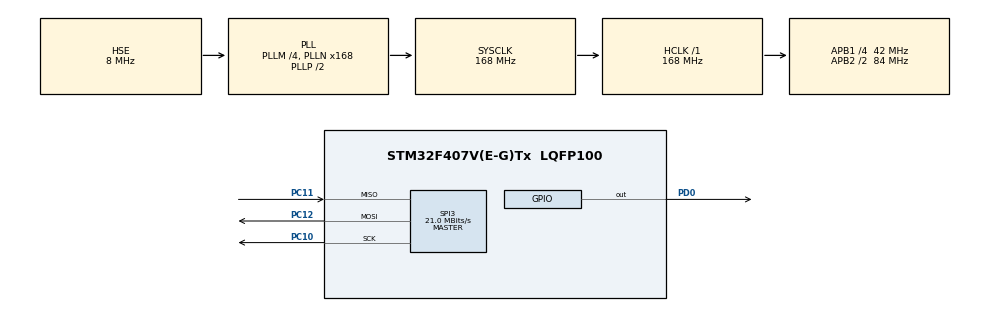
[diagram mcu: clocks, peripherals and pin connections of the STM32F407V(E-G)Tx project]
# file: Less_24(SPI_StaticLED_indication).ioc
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Mcu.Family=STM32F4
Mcu.Name=STM32F407V(E-G)Tx
Mcu.Package=LQFP100
NVIC.PriorityGroup=NVIC_PRIORITYGROUP_4
PC10.Mode=Full_Duplex_Master
PC10.Signal=SPI3_SCK
PC11.Mode=Full_Duplex_Master
PC11.Signal=SPI3_MISO
PC12.Mode=Full_Duplex_Master
PC12.Signal=SPI3_MOSI
PD0.Signal=GPIO_Output
PH0-OSC_IN.Mode=HSE-External-Oscillator
PH0-OSC_IN.Signal=RCC_OSC_IN
PH1-OSC_OUT.Mode=HSE-External-Oscillator
PH1-OSC_OUT.Signal=RCC_OSC_OUT
ProjectManager.HeapSize=0x200
ProjectManager.StackSize=0x400
ProjectManager.TargetToolchain=MDK-ARM V5
RCC.48MHZClocksFreq_Value=84000000
RCC.AHBFreq_Value=168000000
RCC.APB1CLKDivider=RCC_HCLK_DIV4
RCC.APB1Freq_Value=42000000
RCC.APB1TimFreq_Value=84000000
RCC.APB2CLKDivider=RCC_HCLK_DIV2
RCC.APB2Freq_Value=84000000
RCC.APB2TimFreq_Value=168000000
RCC.CortexFreq_Value=168000000
RCC.HCLKFreq_Value=168000000
RCC.HSE_VALUE=8000000
RCC.HSI_VALUE=16000000
RCC.LSE_VALUE=32768
RCC.PLLM=4
RCC.PLLN=168
RCC.PLLSourceVirtual=RCC_PLLSOURCE_HSE
RCC.SYSCLKFreq_VALUE=168000000
RCC.SYSCLKSource=RCC_SYSCLKSOURCE_PLLCLK
RCC.VCOOutputFreq_Value=336000000
SPI3.BaudRatePrescaler=SPI_BAUDRATEPRESCALER_2
SPI3.CalculateBaudRate=21.0 MBits/s
SPI3.Mode=SPI_MODE_MASTER
board=Less_24(SPI_StaticLED_indication)

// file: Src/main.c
#include "main.h"
#include "stm32f4xx_hal.h"

/* USER CODE BEGIN Includes */
#define cs_set() HAL_GPIO_WritePin(GPIOD, GPIO_PIN_0, GPIO_PIN_RESET)
#define cs_reset() HAL_GPIO_WritePin(GPIOD, GPIO_PIN_0, GPIO_PIN_SET)
#define cs_strob() cs_reset();cs_set()
/* USER CODE END Includes */

SPI_HandleTypeDef hspi3;
uint8_t data[1];
/* USER CODE BEGIN PV */
/* Private variables ---------------------------------------------------------*/

/* USER CODE END PV */

void SystemClock_Config(void);
void Error_Handler(void);
static void MX_GPIO_Init(void);
static void MX_SPI3_Init(void);

/* USER CODE BEGIN PFP */
/* Private function prototypes -----------------------------------------------*/

/* USER CODE END PFP */

int main(void)
{

  /* USER CODE BEGIN 1 */

	data[0]=6;
  /* USER CODE END 1 */

  /* MCU Configuration----------------------------------------------------------*/

  /* Reset of all peripherals, Initializes the Flash interface and the Systick. */
  HAL_Init();

  /* Configure the system clock */
  SystemClock_Config();

  /* Initialize all configured peripherals */
  MX_GPIO_Init();
  MX_SPI3_Init();
cs_set();

	HAL_SPI_Transmit(&hspi3,(uint8_t*)data,1,5000);
  /* USER CODE BEGIN 2 */
cs_strob();
  /* USER CODE END 2 */

  /* Infinite loop */
  /* USER CODE BEGIN WHILE */
  while (1)
  {
  for(int i=0;i<=9;i++){

		segchar(i);

		HAL_Delay(500);

	}
  }
  /* USER CODE END 3 */

}

/** System Clock Configuration
*/
void SystemClock_Config(void)
{

  RCC_OscInitTypeDef RCC_OscInitStruct;
  RCC_ClkInitTypeDef RCC_ClkInitStruct;

    /**Configure the main internal regulator output voltage
    */
  __HAL_RCC_PWR_CLK_ENABLE();

  __HAL_PWR_VOLTAGESCALING_CONFIG(PWR_REGULATOR_VOLTAGE_SCALE1);

    /**Initializes the CPU, AHB and APB busses clocks
    */
  RCC_OscInitStruct.OscillatorType = RCC_OSCILLATORTYPE_HSE;
  RCC_OscInitStruct.HSEState = RCC_HSE_ON;
  RCC_OscInitStruct.PLL.PLLState = RCC_PLL_ON;
  RCC_OscInitStruct.PLL.PLLSource = RCC_PLLSOURCE_HSE;
  RCC_OscInitStruct.PLL.PLLM = 4;
  RCC_OscInitStruct.PLL.PLLN = 168;
  RCC_OscInitStruct.PLL.PLLP = RCC_PLLP_DIV2;
  RCC_OscInitStruct.PLL.PLLQ = 4;
  if (HAL_RCC_OscConfig(&RCC_OscInitStruct) != HAL_OK)
  {
    Error_Handler();
  }

    /**Initializes the CPU, AHB and APB busses clocks
    */
  RCC_ClkInitStruct.ClockType = RCC_CLOCKTYPE_HCLK|RCC_CLOCKTYPE_SYSCLK
                              |RCC_CLOCKTYPE_PCLK1|RCC_CLOCKTYPE_PCLK2;
  RCC_ClkInitStruct.SYSCLKSource = RCC_SYSCLKSOURCE_PLLCLK;
  RCC_ClkInitStruct.AHBCLKDivider = RCC_SYSCLK_DIV1;
  RCC_ClkInitStruct.APB1CLKDivider = RCC_HCLK_DIV4;
  RCC_ClkInitStruct.APB2CLKDivider = RCC_HCLK_DIV2;

  if (HAL_RCC_ClockConfig(&RCC_ClkInitStruct, FLASH_LATENCY_5) != HAL_OK)
  {
    Error_Handler();
  }

    /**Configure the Systick interrupt time
    */
  HAL_SYSTICK_Config(HAL_RCC_GetHCLKFreq()/1000);

    /**Configure the Systick
    */
  HAL_SYSTICK_CLKSourceConfig(SYSTICK_CLKSOURCE_HCLK);

  /* SysTick_IRQn interrupt configuration */
  HAL_NVIC_SetPriority(SysTick_IRQn, 0, 0);
}

/* SPI3 init function */
static void MX_SPI3_Init(void)
{

  hspi3.Instance = SPI3;
  hspi3.Init.Mode = SPI_MODE_MASTER;
  hspi3.Init.Direction = SPI_DIRECTION_2LINES;
  hspi3.Init.DataSize = SPI_DATASIZE_8BIT;
  hspi3.Init.CLKPolarity = SPI_POLARITY_LOW;
  hspi3.Init.CLKPhase = SPI_PHASE_1EDGE;
  hspi3.Init.NSS = SPI_NSS_SOFT;
  hspi3.Init.BaudRatePrescaler = SPI_BAUDRATEPRESCALER_2;
  hspi3.Init.FirstBit = SPI_FIRSTBIT_MSB;
  hspi3.Init.TIMode = SPI_TIMODE_DISABLE;
  hspi3.Init.CRCCalculation = SPI_CRCCALCULATION_DISABLE;
  hspi3.Init.CRCPolynomial = 10;
  if (HAL_SPI_Init(&hspi3) != HAL_OK)
  {
    Error_Handler();
  }

}

/** Configure pins as
        * Analog
        * Input
        * Output
        * EVENT_OUT
        * EXTI
*/
static void MX_GPIO_Init(void)
{

  GPIO_InitTypeDef GPIO_InitStruct;

  /* GPIO Ports Clock Enable */
  __HAL_RCC_GPIOH_CLK_ENABLE();
  __HAL_RCC_GPIOC_CLK_ENABLE();
  __HAL_RCC_GPIOD_CLK_ENABLE();

  /*Configure GPIO pin Output Level */
  HAL_GPIO_WritePin(GPIOD, GPIO_PIN_0, GPIO_PIN_RESET);

  /*Configure GPIO pin : PD0 */
  GPIO_InitStruct.Pin = GPIO_PIN_0;
  GPIO_InitStruct.Mode = GPIO_MODE_OUTPUT_PP;
  GPIO_InitStruct.Pull = GPIO_NOPULL;
  GPIO_InitStruct.Speed = GPIO_SPEED_FREQ_LOW;
  HAL_GPIO_Init(GPIOD, &GPIO_InitStruct);

}

void Error_Handler(void)
{
  while(1)
  {
  }
}

/************************ (C) COPYRIGHT STMicroelectronics *****END OF FILE****/
